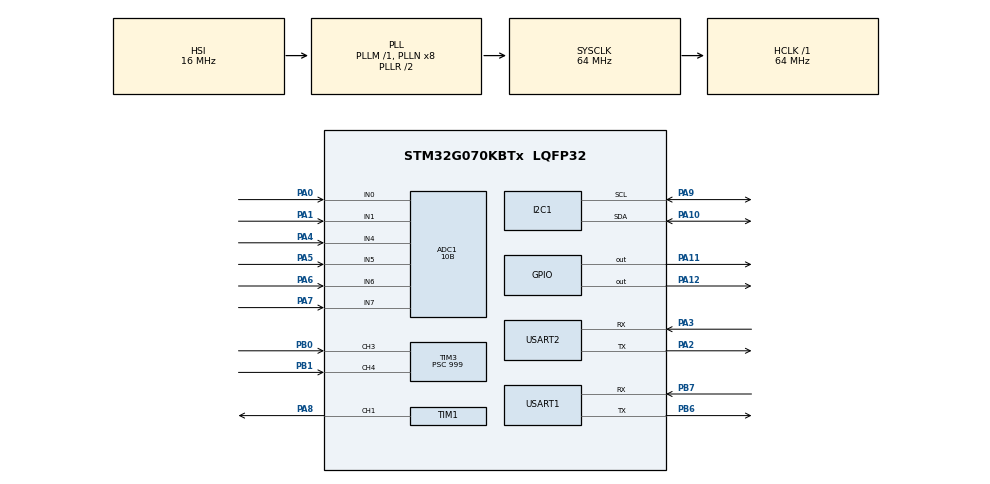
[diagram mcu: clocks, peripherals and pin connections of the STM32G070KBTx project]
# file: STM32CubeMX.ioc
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ADC1.Channel-0\#ChannelRegularConversion=ADC_CHANNEL_0
ADC1.Channel-1\#ChannelRegularConversion=ADC_CHANNEL_1
ADC1.Channel-2\#ChannelRegularConversion=ADC_CHANNEL_4
ADC1.Channel-3\#ChannelRegularConversion=ADC_CHANNEL_5
ADC1.Channel-4\#ChannelRegularConversion=ADC_CHANNEL_6
ADC1.Channel-5\#ChannelRegularConversion=ADC_CHANNEL_7
ADC1.Channel-6\#ChannelRegularConversion=ADC_CHANNEL_TEMPSENSOR
ADC1.Channel-7\#ChannelRegularConversion=ADC_CHANNEL_VREFINT
ADC1.ClockPrescaler=ADC_CLOCK_SYNC_PCLK_DIV4
ADC1.DMAContinuousRequests=ENABLE
ADC1.EOCSelection=ADC_EOC_SEQ_CONV
ADC1.ExternalTrigConv=ADC_EXTERNALTRIG_T15_TRGO
ADC1.ExternalTrigConvEdge=ADC_EXTERNALTRIGCONVEDGE_FALLING
ADC1.NbrOfConversion=8
ADC1.NbrOfConversionFlag=1
ADC1.OversamplingMode=DISABLE
ADC1.Rank-0\#ChannelRegularConversion=1
ADC1.Rank-1\#ChannelRegularConversion=2
ADC1.Rank-2\#ChannelRegularConversion=3
ADC1.Rank-3\#ChannelRegularConversion=4
ADC1.Rank-4\#ChannelRegularConversion=5
ADC1.Rank-5\#ChannelRegularConversion=6
ADC1.Rank-6\#ChannelRegularConversion=7
ADC1.Rank-7\#ChannelRegularConversion=8
ADC1.Resolution=ADC_RESOLUTION_10B
ADC1.SamplingTime-0\#ChannelRegularConversion=ADC_SAMPLINGTIME_COMMON_1
ADC1.SamplingTime-1\#ChannelRegularConversion=ADC_SAMPLINGTIME_COMMON_1
ADC1.SamplingTime-2\#ChannelRegularConversion=ADC_SAMPLINGTIME_COMMON_1
ADC1.SamplingTime-3\#ChannelRegularConversion=ADC_SAMPLINGTIME_COMMON_1
ADC1.SamplingTime-4\#ChannelRegularConversion=ADC_SAMPLINGTIME_COMMON_1
ADC1.SamplingTime-5\#ChannelRegularConversion=ADC_SAMPLINGTIME_COMMON_1
ADC1.SamplingTime-6\#ChannelRegularConversion=ADC_SAMPLINGTIME_COMMON_1
ADC1.SamplingTime-7\#ChannelRegularConversion=ADC_SAMPLINGTIME_COMMON_1
ADC1.SamplingTimeCommon1=ADC_SAMPLETIME_160CYCLES_5
ADC1.SamplingTimeCommon2=ADC_SAMPLETIME_160CYCLES_5
ADC1.SelectedChannel=ADC_CHANNEL_0|ADC_CHANNEL_1|ADC_CHANNEL_4|ADC_CHANNEL_5|ADC_CHANNEL_6|ADC_CHANNEL_7|ADC_CHANNEL_TEMPSENSOR|ADC_CHANNEL_VREFINT
ADC1.TriggerFrequencyMode=ADC_TRIGGER_FREQ_HIGH
ADC1.master=1
Dma.ADC1.0.Direction=DMA_PERIPH_TO_MEMORY
Dma.ADC1.0.EventEnable=DISABLE
Dma.ADC1.0.Instance=DMA1_Channel1
Dma.ADC1.0.MemDataAlignment=DMA_MDATAALIGN_HALFWORD
Dma.ADC1.0.MemInc=DMA_MINC_ENABLE
Dma.ADC1.0.Mode=DMA_CIRCULAR
Dma.ADC1.0.PeriphDataAlignment=DMA_PDATAALIGN_HALFWORD
Dma.ADC1.0.PeriphInc=DMA_PINC_DISABLE
Dma.ADC1.0.Polarity=HAL_DMAMUX_REQ_GEN_RISING
Dma.ADC1.0.Priority=DMA_PRIORITY_HIGH
Dma.ADC1.0.RequestNumber=1
Dma.ADC1.0.SignalID=NONE
Dma.ADC1.0.SyncEnable=DISABLE
Dma.ADC1.0.SyncPolarity=HAL_DMAMUX_SYNC_NO_EVENT
Dma.ADC1.0.SyncRequestNumber=1
Dma.ADC1.0.SyncSignalID=NONE
Dma.Request0=ADC1
I2C1.Timing=0x10B17DB5
Mcu.Family=STM32G0
Mcu.Name=STM32G070KBTx
Mcu.Package=LQFP32
NVIC.DMA1_Channel1_IRQn=true\:2\:0\:true\:false\:true\:false\:true\:true
NVIC.I2C1_IRQn=true\:2\:0\:true\:false\:true\:true\:true\:true
NVIC.TIM14_IRQn=true\:3\:0\:false\:false\:true\:false\:true\:true
NVIC.TIM3_IRQn=true\:1\:0\:true\:false\:true\:true\:true\:true
NVIC.TimeBase=TIM14_IRQn
NVIC.TimeBaseIP=TIM14
NVIC.USART1_IRQn=true\:2\:0\:true\:false\:true\:true\:false\:true
NVIC.USART2_IRQn=true\:2\:0\:true\:false\:true\:true\:true\:true
PA0.Mode=IN0
PA0.Signal=ADC1_IN0
PA1.Mode=IN1
PA1.Signal=ADC1_IN1
PA10.Mode=I2C
PA10.Signal=I2C1_SDA
PA11\ [PA9].Signal=GPIO_Output
PA12\ [PA10].Signal=GPIO_Output
PA13.Mode=Serial_Wire
PA13.Signal=SYS_SWDIO
PA14-BOOT0.Mode=Serial_Wire
PA14-BOOT0.Signal=SYS_SWCLK
PA2.Mode=Asynchronous
PA2.Signal=USART2_TX
PA3.Mode=Asynchronous
PA3.Signal=USART2_RX
PA4.Mode=IN4
PA4.Signal=ADC1_IN4
PA5.Mode=IN5
PA5.Signal=ADC1_IN5
PA6.Mode=IN6
PA6.Signal=ADC1_IN6
PA7.Mode=IN7
PA7.Signal=ADC1_IN7
PA8.Signal=S_TIM1_CH1
PA9.Mode=I2C
PA9.Signal=I2C1_SCL
PB0.Signal=S_TIM3_CH3
PB1.Signal=S_TIM3_CH4
PB6.Mode=Asynchronous
PB6.Signal=USART1_TX
PB7.Mode=Asynchronous
PB7.Signal=USART1_RX
ProjectManager.HeapSize=0x800
ProjectManager.StackSize=0x800
ProjectManager.TargetToolchain=MDK-ARM V5
RCC.ADCFreq_Value=64000000
RCC.AHBFreq_Value=64000000
RCC.CortexFreq_Value=64000000
RCC.EXTERNAL_CLOCK_VALUE=48000
RCC.HCLKFreq_Value=64000000
RCC.HSE_VALUE=8000000
RCC.HSI_VALUE=16000000
RCC.LSE_VALUE=32768
RCC.SYSCLKFreq_VALUE=64000000
RCC.SYSCLKSource=RCC_SYSCLKSOURCE_PLLCLK
RCC.VCOOutputFreq_Value=128000000
SH.S_TIM1_CH1.0=TIM1_CH1,PWM Generation1 CH1
SH.S_TIM3_CH3.0=TIM3_CH3,Input_Capture3_from_TI3
SH.S_TIM3_CH4.0=TIM3_CH4,Input_Capture4_from_TI4
TIM1.AutoReloadPreload=TIM_AUTORELOAD_PRELOAD_ENABLE
TIM1.Channel-PWM\ Generation1\ CH1=TIM_CHANNEL_1
TIM1.OCIdleState_1=TIM_OCIDLESTATE_SET
TIM1.OCPolarity_1=TIM_OCPOLARITY_LOW
TIM1.Period=2559
TIM15.Channel-PWM\ Generation1\ No\ Output=TIM_CHANNEL_1
TIM15.Period=7999
TIM15.Prescaler=999
TIM15.Pulse-PWM\ Generation1\ No\ Output=4000
TIM15.TIM_MasterOutputTrigger=TIM_TRGO_OC1REF
TIM15.TIM_MasterSlaveMode=TIM_MASTERSLAVEMODE_ENABLE
TIM3.AutoReloadPreload=TIM_AUTORELOAD_PRELOAD_ENABLE
TIM3.Channel-Input_Capture3_from_TI3=TIM_CHANNEL_3
TIM3.Channel-Input_Capture4_from_TI4=TIM_CHANNEL_4
TIM3.ICFilter_CH3=8
TIM3.ICFilter_CH4=8
TIM3.Period=63999
TIM3.Prescaler=999
TIM3.TIM_MasterSlaveMode=TIM_MASTERSLAVEMODE_ENABLE
USART1.VirtualMode-Asynchronous=VM_ASYNC
USART2.VirtualMode-Asynchronous=VM_ASYNC
VP_ADC1_TempSens_Input.Mode=IN-TempSens
VP_ADC1_Vref_Input.Mode=IN-Vrefint
VP_SYS_VS_tim14.Mode=TIM14
VP_TIM15_VS_ClockSourceINT.Mode=Internal
VP_TIM15_VS_ClockSourceITR.Mode=TriggerSource_ITR1
VP_TIM15_VS_ControllerModeReset.Mode=Reset Mode
VP_TIM15_VS_no_output1.Mode=PWM Generation1 No Output
VP_TIM1_VS_ClockSourceINT.Mode=Internal
VP_TIM3_VS_ClockSourceINT.Mode=Internal
board=custom

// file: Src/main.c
/* USER CODE BEGIN Header */
/**
  ******************************************************************************
  * @file           : main.c
  * @brief          : Main program body
  ******************************************************************************
  * @attention
  *
  * Copyright (c) 2025 STMicroelectronics.
  * All rights reserved.
  *
  * This software is licensed under terms that can be found in the LICENSE file
  * in the root directory of this software component.
  * If no LICENSE file comes with this software, it is provided AS-IS.
  *
  ******************************************************************************
  */
/* USER CODE END Header */
#include "main.h"

ADC_HandleTypeDef hadc1;
DMA_HandleTypeDef hdma_adc1;

I2C_HandleTypeDef hi2c1;

TIM_HandleTypeDef htim1;
TIM_HandleTypeDef htim3;
TIM_HandleTypeDef htim15;

UART_HandleTypeDef huart1;
UART_HandleTypeDef huart2;

void SystemClock_Config(void);
static void MX_GPIO_Init(void);
static void MX_DMA_Init(void);
static void MX_ADC1_Init(void);
static void MX_I2C1_Init(void);
static void MX_USART1_UART_Init(void);
static void MX_USART2_UART_Init(void);
static void MX_TIM1_Init(void);
static void MX_TIM3_Init(void);
static void MX_TIM15_Init(void);
/* USER CODE BEGIN PFP */
extern int app_main(void);
extern void CAP_TIM_PeriodElapsedCallback(TIM_HandleTypeDef *htim);
/* USER CODE END PFP */

int main(void)
{

  /* MCU Configuration--------------------------------------------------------*/

  /* Reset of all peripherals, Initializes the Flash interface and the Systick. */
  HAL_Init();

  /* Configure the system clock */
  SystemClock_Config();

  /* Initialize all configured peripherals */
  MX_GPIO_Init();
  MX_DMA_Init();
  MX_ADC1_Init();
  MX_I2C1_Init();
  MX_USART1_UART_Init();
  MX_USART2_UART_Init();
  MX_TIM1_Init();
  MX_TIM3_Init();
  MX_TIM15_Init();
  /* USER CODE BEGIN 2 */
  app_main(); // Call the main application function
  /* USER CODE END 2 */

  /* Infinite loop */
  while (1)
  {

  }
}

void SystemClock_Config(void)
{
  RCC_OscInitTypeDef RCC_OscInitStruct = {0};
  RCC_ClkInitTypeDef RCC_ClkInitStruct = {0};

  /** Configure the main internal regulator output voltage
  */
  HAL_PWREx_ControlVoltageScaling(PWR_REGULATOR_VOLTAGE_SCALE1);

  /** Initializes the RCC Oscillators according to the specified parameters
  * in the RCC_OscInitTypeDef structure.
  */
  RCC_OscInitStruct.OscillatorType = RCC_OSCILLATORTYPE_HSI;
  RCC_OscInitStruct.HSIState = RCC_HSI_ON;
  RCC_OscInitStruct.HSIDiv = RCC_HSI_DIV1;
  RCC_OscInitStruct.HSICalibrationValue = RCC_HSICALIBRATION_DEFAULT;
  RCC_OscInitStruct.PLL.PLLState = RCC_PLL_ON;
  RCC_OscInitStruct.PLL.PLLSource = RCC_PLLSOURCE_HSI;
  RCC_OscInitStruct.PLL.PLLM = RCC_PLLM_DIV1;
  RCC_OscInitStruct.PLL.PLLN = 8;
  RCC_OscInitStruct.PLL.PLLP = RCC_PLLP_DIV2;
  RCC_OscInitStruct.PLL.PLLR = RCC_PLLR_DIV2;
  if (HAL_RCC_OscConfig(&RCC_OscInitStruct) != HAL_OK)
  {
    Error_Handler();
  }

  /** Initializes the CPU, AHB and APB buses clocks
  */
  RCC_ClkInitStruct.ClockType = RCC_CLOCKTYPE_HCLK|RCC_CLOCKTYPE_SYSCLK
                              |RCC_CLOCKTYPE_PCLK1;
  RCC_ClkInitStruct.SYSCLKSource = RCC_SYSCLKSOURCE_PLLCLK;
  RCC_ClkInitStruct.AHBCLKDivider = RCC_SYSCLK_DIV1;
  RCC_ClkInitStruct.APB1CLKDivider = RCC_HCLK_DIV1;

  if (HAL_RCC_ClockConfig(&RCC_ClkInitStruct, FLASH_LATENCY_2) != HAL_OK)
  {
    Error_Handler();
  }
}

static void MX_ADC1_Init(void)
{

  ADC_ChannelConfTypeDef sConfig = {0};

  /** Configure the global features of the ADC (Clock, Resolution, Data Alignment and number of conversion)
  */
  hadc1.Instance = ADC1;
  hadc1.Init.ClockPrescaler = ADC_CLOCK_SYNC_PCLK_DIV4;
  hadc1.Init.Resolution = ADC_RESOLUTION_10B;
  hadc1.Init.DataAlign = ADC_DATAALIGN_RIGHT;
  hadc1.Init.ScanConvMode = ADC_SCAN_ENABLE;
  hadc1.Init.EOCSelection = ADC_EOC_SEQ_CONV;
  hadc1.Init.LowPowerAutoWait = DISABLE;
  hadc1.Init.LowPowerAutoPowerOff = DISABLE;
  hadc1.Init.ContinuousConvMode = DISABLE;
  hadc1.Init.NbrOfConversion = 8;
  hadc1.Init.DiscontinuousConvMode = DISABLE;
  hadc1.Init.ExternalTrigConv = ADC_EXTERNALTRIG_T15_TRGO;
  hadc1.Init.ExternalTrigConvEdge = ADC_EXTERNALTRIGCONVEDGE_FALLING;
  hadc1.Init.DMAContinuousRequests = ENABLE;
  hadc1.Init.Overrun = ADC_OVR_DATA_PRESERVED;
  hadc1.Init.SamplingTimeCommon1 = ADC_SAMPLETIME_160CYCLES_5;
  hadc1.Init.SamplingTimeCommon2 = ADC_SAMPLETIME_160CYCLES_5;
  hadc1.Init.OversamplingMode = DISABLE;
  hadc1.Init.TriggerFrequencyMode = ADC_TRIGGER_FREQ_HIGH;
  if (HAL_ADC_Init(&hadc1) != HAL_OK)
  {
    Error_Handler();
  }

  /** Configure Regular Channel
  */
  sConfig.Channel = ADC_CHANNEL_0;
  sConfig.Rank = ADC_REGULAR_RANK_1;
  sConfig.SamplingTime = ADC_SAMPLINGTIME_COMMON_1;
  if (HAL_ADC_ConfigChannel(&hadc1, &sConfig) != HAL_OK)
  {
    Error_Handler();
  }

  /** Configure Regular Channel
  */
  sConfig.Channel = ADC_CHANNEL_1;
  sConfig.Rank = ADC_REGULAR_RANK_2;
  if (HAL_ADC_ConfigChannel(&hadc1, &sConfig) != HAL_OK)
  {
    Error_Handler();
  }

  /** Configure Regular Channel
  */
  sConfig.Channel = ADC_CHANNEL_4;
  sConfig.Rank = ADC_REGULAR_RANK_3;
  if (HAL_ADC_ConfigChannel(&hadc1, &sConfig) != HAL_OK)
  {
    Error_Handler();
  }

  /** Configure Regular Channel
  */
  sConfig.Channel = ADC_CHANNEL_5;
  sConfig.Rank = ADC_REGULAR_RANK_4;
  if (HAL_ADC_ConfigChannel(&hadc1, &sConfig) != HAL_OK)
  {
    Error_Handler();
  }

  /** Configure Regular Channel
  */
  sConfig.Channel = ADC_CHANNEL_6;
  sConfig.Rank = ADC_REGULAR_RANK_5;
  if (HAL_ADC_ConfigChannel(&hadc1, &sConfig) != HAL_OK)
  {
    Error_Handler();
  }

  /** Configure Regular Channel
  */
  sConfig.Channel = ADC_CHANNEL_7;
  sConfig.Rank = ADC_REGULAR_RANK_6;
  if (HAL_ADC_ConfigChannel(&hadc1, &sConfig) != HAL_OK)
  {
    Error_Handler();
  }

  /** Configure Regular Channel
  */
  sConfig.Channel = ADC_CHANNEL_TEMPSENSOR;
  sConfig.Rank = ADC_REGULAR_RANK_7;
  if (HAL_ADC_ConfigChannel(&hadc1, &sConfig) != HAL_OK)
  {
    Error_Handler();
  }

  /** Configure Regular Channel
  */
  sConfig.Channel = ADC_CHANNEL_VREFINT;
  sConfig.Rank = ADC_REGULAR_RANK_8;
  if (HAL_ADC_ConfigChannel(&hadc1, &sConfig) != HAL_OK)
  {
    Error_Handler();
  }

}

static void MX_I2C1_Init(void)
{

  hi2c1.Instance = I2C1;
  hi2c1.Init.Timing = 0x10B17DB5;
  hi2c1.Init.OwnAddress1 = 0;
  hi2c1.Init.AddressingMode = I2C_ADDRESSINGMODE_7BIT;
  hi2c1.Init.DualAddressMode = I2C_DUALADDRESS_DISABLE;
  hi2c1.Init.OwnAddress2 = 0;
  hi2c1.Init.OwnAddress2Masks = I2C_OA2_NOMASK;
  hi2c1.Init.GeneralCallMode = I2C_GENERALCALL_DISABLE;
  hi2c1.Init.NoStretchMode = I2C_NOSTRETCH_DISABLE;
  if (HAL_I2C_Init(&hi2c1) != HAL_OK)
  {
    Error_Handler();
  }

  /** Configure Analogue filter
  */
  if (HAL_I2CEx_ConfigAnalogFilter(&hi2c1, I2C_ANALOGFILTER_ENABLE) != HAL_OK)
  {
    Error_Handler();
  }

  /** Configure Digital filter
  */
  if (HAL_I2CEx_ConfigDigitalFilter(&hi2c1, 0) != HAL_OK)
  {
    Error_Handler();
  }

}

static void MX_TIM1_Init(void)
{

  TIM_ClockConfigTypeDef sClockSourceConfig = {0};
  TIM_MasterConfigTypeDef sMasterConfig = {0};
  TIM_OC_InitTypeDef sConfigOC = {0};
  TIM_BreakDeadTimeConfigTypeDef sBreakDeadTimeConfig = {0};

  htim1.Instance = TIM1;
  htim1.Init.Prescaler = 0;
  htim1.Init.CounterMode = TIM_COUNTERMODE_UP;
  htim1.Init.Period = 2559;
  htim1.Init.ClockDivision = TIM_CLOCKDIVISION_DIV1;
  htim1.Init.RepetitionCounter = 0;
  htim1.Init.AutoReloadPreload = TIM_AUTORELOAD_PRELOAD_ENABLE;
  if (HAL_TIM_Base_Init(&htim1) != HAL_OK)
  {
    Error_Handler();
  }
  sClockSourceConfig.ClockSource = TIM_CLOCKSOURCE_INTERNAL;
  if (HAL_TIM_ConfigClockSource(&htim1, &sClockSourceConfig) != HAL_OK)
  {
    Error_Handler();
  }
  if (HAL_TIM_PWM_Init(&htim1) != HAL_OK)
  {
    Error_Handler();
  }
  sMasterConfig.MasterOutputTrigger = TIM_TRGO_RESET;
  sMasterConfig.MasterOutputTrigger2 = TIM_TRGO2_RESET;
  sMasterConfig.MasterSlaveMode = TIM_MASTERSLAVEMODE_DISABLE;
  if (HAL_TIMEx_MasterConfigSynchronization(&htim1, &sMasterConfig) != HAL_OK)
  {
    Error_Handler();
  }
  sConfigOC.OCMode = TIM_OCMODE_PWM1;
  sConfigOC.Pulse = 0;
  sConfigOC.OCPolarity = TIM_OCPOLARITY_LOW;
  sConfigOC.OCNPolarity = TIM_OCNPOLARITY_HIGH;
  sConfigOC.OCFastMode = TIM_OCFAST_DISABLE;
  sConfigOC.OCIdleState = TIM_OCIDLESTATE_SET;
  sConfigOC.OCNIdleState = TIM_OCNIDLESTATE_RESET;
  if (HAL_TIM_PWM_ConfigChannel(&htim1, &sConfigOC, TIM_CHANNEL_1) != HAL_OK)
  {
    Error_Handler();
  }
  sBreakDeadTimeConfig.OffStateRunMode = TIM_OSSR_DISABLE;
  sBreakDeadTimeConfig.OffStateIDLEMode = TIM_OSSI_DISABLE;
  sBreakDeadTimeConfig.LockLevel = TIM_LOCKLEVEL_OFF;
  sBreakDeadTimeConfig.DeadTime = 0;
  sBreakDeadTimeConfig.BreakState = TIM_BREAK_DISABLE;
  sBreakDeadTimeConfig.BreakPolarity = TIM_BREAKPOLARITY_HIGH;
  sBreakDeadTimeConfig.BreakFilter = 0;
  sBreakDeadTimeConfig.BreakAFMode = TIM_BREAK_AFMODE_INPUT;
  sBreakDeadTimeConfig.Break2State = TIM_BREAK2_DISABLE;
  sBreakDeadTimeConfig.Break2Polarity = TIM_BREAK2POLARITY_HIGH;
  sBreakDeadTimeConfig.Break2Filter = 0;
  sBreakDeadTimeConfig.Break2AFMode = TIM_BREAK_AFMODE_INPUT;
  sBreakDeadTimeConfig.AutomaticOutput = TIM_AUTOMATICOUTPUT_DISABLE;
  if (HAL_TIMEx_ConfigBreakDeadTime(&htim1, &sBreakDeadTimeConfig) != HAL_OK)
  {
    Error_Handler();
  }
  HAL_TIM_MspPostInit(&htim1);

}

static void MX_TIM3_Init(void)
{

  TIM_ClockConfigTypeDef sClockSourceConfig = {0};
  TIM_MasterConfigTypeDef sMasterConfig = {0};
  TIM_IC_InitTypeDef sConfigIC = {0};

  htim3.Instance = TIM3;
  htim3.Init.Prescaler = 999;
  htim3.Init.CounterMode = TIM_COUNTERMODE_UP;
  htim3.Init.Period = 63999;
  htim3.Init.ClockDivision = TIM_CLOCKDIVISION_DIV1;
  htim3.Init.AutoReloadPreload = TIM_AUTORELOAD_PRELOAD_ENABLE;
  if (HAL_TIM_Base_Init(&htim3) != HAL_OK)
  {
    Error_Handler();
  }
  sClockSourceConfig.ClockSource = TIM_CLOCKSOURCE_INTERNAL;
  if (HAL_TIM_ConfigClockSource(&htim3, &sClockSourceConfig) != HAL_OK)
  {
    Error_Handler();
  }
  if (HAL_TIM_IC_Init(&htim3) != HAL_OK)
  {
    Error_Handler();
  }
  sMasterConfig.MasterOutputTrigger = TIM_TRGO_RESET;
  sMasterConfig.MasterSlaveMode = TIM_MASTERSLAVEMODE_ENABLE;
  if (HAL_TIMEx_MasterConfigSynchronization(&htim3, &sMasterConfig) != HAL_OK)
  {
    Error_Handler();
  }
  sConfigIC.ICPolarity = TIM_INPUTCHANNELPOLARITY_RISING;
  sConfigIC.ICSelection = TIM_ICSELECTION_DIRECTTI;
  sConfigIC.ICPrescaler = TIM_ICPSC_DIV1;
  sConfigIC.ICFilter = 8;
  if (HAL_TIM_IC_ConfigChannel(&htim3, &sConfigIC, TIM_CHANNEL_3) != HAL_OK)
  {
    Error_Handler();
  }
  if (HAL_TIM_IC_ConfigChannel(&htim3, &sConfigIC, TIM_CHANNEL_4) != HAL_OK)
  {
    Error_Handler();
  }

}

static void MX_TIM15_Init(void)
{

  TIM_ClockConfigTypeDef sClockSourceConfig = {0};
  TIM_SlaveConfigTypeDef sSlaveConfig = {0};
  TIM_MasterConfigTypeDef sMasterConfig = {0};
  TIM_OC_InitTypeDef sConfigOC = {0};
  TIM_BreakDeadTimeConfigTypeDef sBreakDeadTimeConfig = {0};

  htim15.Instance = TIM15;
  htim15.Init.Prescaler = 999;
  htim15.Init.CounterMode = TIM_COUNTERMODE_UP;
  htim15.Init.Period = 7999;
  htim15.Init.ClockDivision = TIM_CLOCKDIVISION_DIV1;
  htim15.Init.RepetitionCounter = 0;
  htim15.Init.AutoReloadPreload = TIM_AUTORELOAD_PRELOAD_DISABLE;
  if (HAL_TIM_Base_Init(&htim15) != HAL_OK)
  {
    Error_Handler();
  }
  sClockSourceConfig.ClockSource = TIM_CLOCKSOURCE_INTERNAL;
  if (HAL_TIM_ConfigClockSource(&htim15, &sClockSourceConfig) != HAL_OK)
  {
    Error_Handler();
  }
  if (HAL_TIM_PWM_Init(&htim15) != HAL_OK)
  {
    Error_Handler();
  }
  sSlaveConfig.SlaveMode = TIM_SLAVEMODE_RESET;
  sSlaveConfig.InputTrigger = TIM_TS_ITR1;
  if (HAL_TIM_SlaveConfigSynchro(&htim15, &sSlaveConfig) != HAL_OK)
  {
    Error_Handler();
  }
  sMasterConfig.MasterOutputTrigger = TIM_TRGO_OC1REF;
  sMasterConfig.MasterSlaveMode = TIM_MASTERSLAVEMODE_ENABLE;
  if (HAL_TIMEx_MasterConfigSynchronization(&htim15, &sMasterConfig) != HAL_OK)
  {
    Error_Handler();
  }
  sConfigOC.OCMode = TIM_OCMODE_PWM1;
  sConfigOC.Pulse = 4000;
  sConfigOC.OCPolarity = TIM_OCPOLARITY_HIGH;
  sConfigOC.OCNPolarity = TIM_OCNPOLARITY_HIGH;
  sConfigOC.OCFastMode = TIM_OCFAST_DISABLE;
  sConfigOC.OCIdleState = TIM_OCIDLESTATE_RESET;
  sConfigOC.OCNIdleState = TIM_OCNIDLESTATE_RESET;
  if (HAL_TIM_PWM_ConfigChannel(&htim15, &sConfigOC, TIM_CHANNEL_1) != HAL_OK)
  {
    Error_Handler();
  }
  sBreakDeadTimeConfig.OffStateRunMode = TIM_OSSR_DISABLE;
  sBreakDeadTimeConfig.OffStateIDLEMode = TIM_OSSI_DISABLE;
  sBreakDeadTimeConfig.LockLevel = TIM_LOCKLEVEL_OFF;
  sBreakDeadTimeConfig.DeadTime = 0;
  sBreakDeadTimeConfig.BreakState = TIM_BREAK_DISABLE;
  sBreakDeadTimeConfig.BreakPolarity = TIM_BREAKPOLARITY_HIGH;
  sBreakDeadTimeConfig.BreakFilter = 0;
  sBreakDeadTimeConfig.AutomaticOutput = TIM_AUTOMATICOUTPUT_DISABLE;
  if (HAL_TIMEx_ConfigBreakDeadTime(&htim15, &sBreakDeadTimeConfig) != HAL_OK)
  {
    Error_Handler();
  }

}

static void MX_USART1_UART_Init(void)
{

  huart1.Instance = USART1;
  huart1.Init.BaudRate = 115200;
  huart1.Init.WordLength = UART_WORDLENGTH_8B;
  huart1.Init.StopBits = UART_STOPBITS_1;
  huart1.Init.Parity = UART_PARITY_NONE;
  huart1.Init.Mode = UART_MODE_TX_RX;
  huart1.Init.HwFlowCtl = UART_HWCONTROL_NONE;
  huart1.Init.OverSampling = UART_OVERSAMPLING_16;
  huart1.Init.OneBitSampling = UART_ONE_BIT_SAMPLE_DISABLE;
  huart1.Init.ClockPrescaler = UART_PRESCALER_DIV1;
  huart1.AdvancedInit.AdvFeatureInit = UART_ADVFEATURE_NO_INIT;
  if (HAL_UART_Init(&huart1) != HAL_OK)
  {
    Error_Handler();
  }
  if (HAL_UARTEx_SetTxFifoThreshold(&huart1, UART_TXFIFO_THRESHOLD_1_8) != HAL_OK)
  {
    Error_Handler();
  }
  if (HAL_UARTEx_SetRxFifoThreshold(&huart1, UART_RXFIFO_THRESHOLD_1_8) != HAL_OK)
  {
    Error_Handler();
  }
  if (HAL_UARTEx_DisableFifoMode(&huart1) != HAL_OK)
  {
    Error_Handler();
  }

}

static void MX_USART2_UART_Init(void)
{

  huart2.Instance = USART2;
  huart2.Init.BaudRate = 115200;
  huart2.Init.WordLength = UART_WORDLENGTH_8B;
  huart2.Init.StopBits = UART_STOPBITS_1;
  huart2.Init.Parity = UART_PARITY_NONE;
  huart2.Init.Mode = UART_MODE_TX_RX;
  huart2.Init.HwFlowCtl = UART_HWCONTROL_NONE;
  huart2.Init.OverSampling = UART_OVERSAMPLING_16;
  huart2.Init.OneBitSampling = UART_ONE_BIT_SAMPLE_DISABLE;
  huart2.Init.ClockPrescaler = UART_PRESCALER_DIV1;
  huart2.AdvancedInit.AdvFeatureInit = UART_ADVFEATURE_NO_INIT;
  if (HAL_UART_Init(&huart2) != HAL_OK)
  {
    Error_Handler();
  }
  if (HAL_UARTEx_SetTxFifoThreshold(&huart2, UART_TXFIFO_THRESHOLD_1_8) != HAL_OK)
  {
    Error_Handler();
  }
  if (HAL_UARTEx_SetRxFifoThreshold(&huart2, UART_RXFIFO_THRESHOLD_1_8) != HAL_OK)
  {
    Error_Handler();
  }
  if (HAL_UARTEx_DisableFifoMode(&huart2) != HAL_OK)
  {
    Error_Handler();
  }

}

static void MX_DMA_Init(void)
{

  /* DMA controller clock enable */
  __HAL_RCC_DMA1_CLK_ENABLE();

  /* DMA interrupt init */
  /* DMA1_Channel1_IRQn interrupt configuration */
  HAL_NVIC_SetPriority(DMA1_Channel1_IRQn, 2, 0);
  HAL_NVIC_EnableIRQ(DMA1_Channel1_IRQn);

}

static void MX_GPIO_Init(void)
{
  GPIO_InitTypeDef GPIO_InitStruct = {0};

  /* GPIO Ports Clock Enable */
  __HAL_RCC_GPIOA_CLK_ENABLE();
  __HAL_RCC_GPIOB_CLK_ENABLE();

  /*Configure GPIO pin Output Level */
  HAL_GPIO_WritePin(GPIOA, GPIO_PIN_11|GPIO_PIN_12, GPIO_PIN_RESET);

  /*Configure GPIO pins : PA11 PA12 */
  GPIO_InitStruct.Pin = GPIO_PIN_11|GPIO_PIN_12;
  GPIO_InitStruct.Mode = GPIO_MODE_OUTPUT_PP;
  GPIO_InitStruct.Pull = GPIO_NOPULL;
  GPIO_InitStruct.Speed = GPIO_SPEED_FREQ_LOW;
  HAL_GPIO_Init(GPIOA, &GPIO_InitStruct);

}

void HAL_TIM_PeriodElapsedCallback(TIM_HandleTypeDef *htim)
{
  if (htim->Instance == TIM14)
  {
    HAL_IncTick();
  }
  /* USER CODE BEGIN Callback 1 */
  if (htim->Instance == TIM3)
  {
    CAP_TIM_PeriodElapsedCallback(htim); // Call the weak function for CAP timer
  }
  /* USER CODE END Callback 1 */
}

void Error_Handler(void)
{
  __disable_irq();
  while (1)
  {
  }
}
